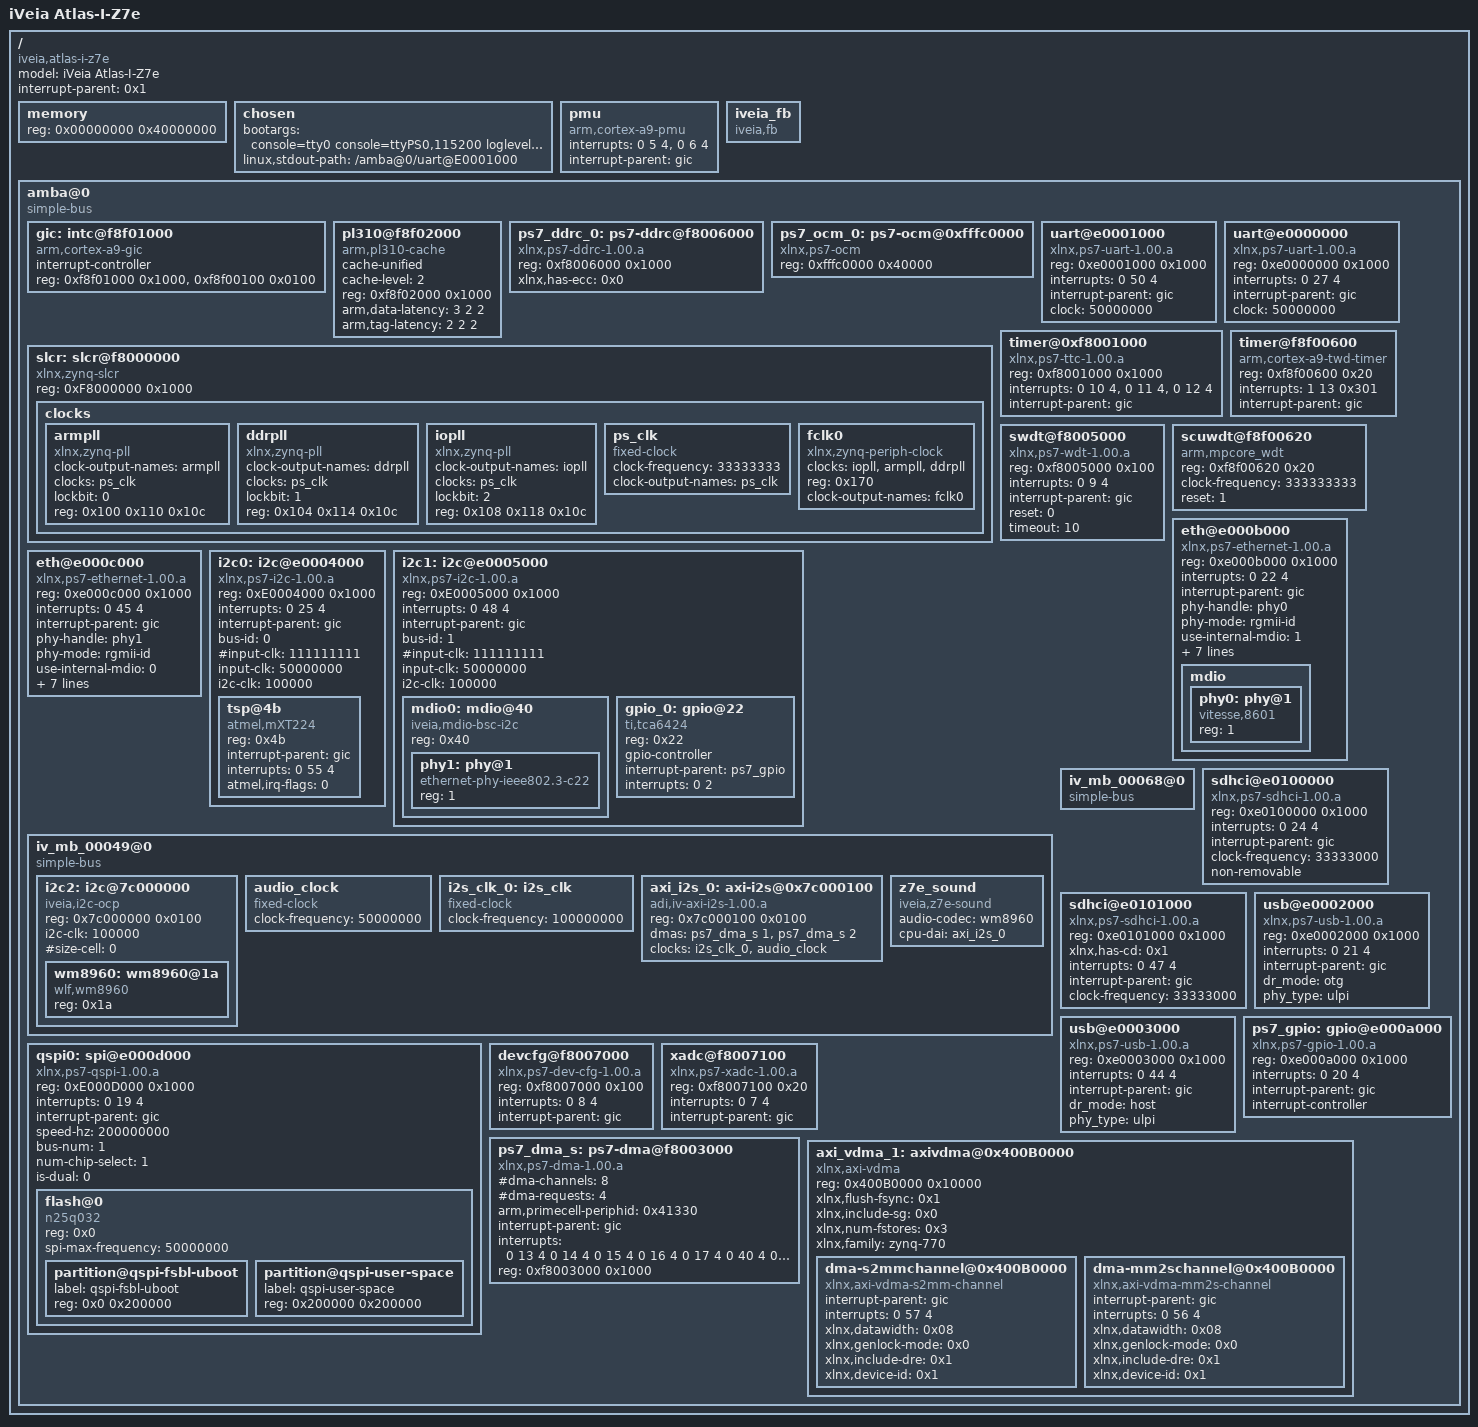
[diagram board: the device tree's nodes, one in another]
/dts-v1/;

/ {
	model = "iVeia Atlas-I-Z7e";
	compatible = "iveia,atlas-i-z7e";
	#address-cells = <0x1>;
	#size-cells = <0x1>;
	interrupt-parent = <0x1>;

	memory {
		device_type = "memory";
		reg = <0x00000000 0x40000000>;
	};
	chosen {
		bootargs = "console=tty0 console=ttyPS0,115200 loglevel=9 qemu=1 root=/dev/ram rw qemu=1 ip=192.168.1.10:::255.255.255.0:ZC702:eth0 earlyprintk mem=768M vram=256M";
//		bootargs = "console=ttyPS0,115200 root=/dev/mmcblk0p3 rw earlyprintk rootfstype=ext4 rootwait devtmpfs.mount=0";
		linux,stdout-path = "/amba@0/uart@E0001000";
	};

	pmu {
		compatible = "arm,cortex-a9-pmu";
		interrupts = <0 5 4>, <0 6 4>;
		interrupt-parent = <&gic>;
	};

	iveia_fb {
		compatible = "iveia,fb";
	};

	amba@0 {
		compatible = "simple-bus";
		#address-cells = <0x1>;
		#size-cells = <0x1>;
		ranges;

		gic: intc@f8f01000 {
			interrupt-controller;
			compatible = "arm,cortex-a9-gic";
			#interrupt-cells = <3>;
			reg = <0xf8f01000 0x1000>,
			      <0xf8f00100 0x0100>;
		};

		pl310@f8f02000 {
			compatible = "arm,pl310-cache";
			cache-unified;
			cache-level = <2>;
			reg = <0xf8f02000 0x1000>;
			arm,data-latency = <3 2 2>;
			arm,tag-latency = <2 2 2>;
		};

		ps7_ddrc_0: ps7-ddrc@f8006000 {
			compatible = "xlnx,ps7-ddrc-1.00.a", "xlnx,ps7-ddrc";
			reg = <0xf8006000 0x1000>;
			xlnx,has-ecc = <0x0>;
		} ;

		ps7_ocm_0: ps7-ocm@0xfffc0000 {
			compatible = "xlnx,ps7-ocm";
			reg = <0xfffc0000 0x40000>; /* 256k */
		};

		uart@e0001000 {
			compatible = "xlnx,ps7-uart-1.00.a";
			reg = <0xe0001000 0x1000>;
			interrupts = <0 50 4>;
			interrupt-parent = <&gic>;
			clock = <50000000>;
		};

		uart@e0000000 {
			compatible = "xlnx,ps7-uart-1.00.a";
			reg = <0xe0000000 0x1000>;
			interrupts = < 0 27 4 >;
			interrupt-parent = <&gic>;
			clock = <50000000>;
		};

		slcr: slcr@f8000000 {
			compatible = "xlnx,zynq-slcr";
			reg = <0xF8000000 0x1000>;
			clocks {
				#address-cells = <1>;
				#size-cells = <0>;	
				armpll: armpll {
                                        #clock-cells = <0>;
                                        clock-output-names = "armpll";
                                        clocks = <&ps_clk>;
                                        compatible = "xlnx,zynq-pll";
                                        lockbit = <0>;
                                        reg = < 0x100 0x110 0x10c >;
                                } ;
                                ddrpll: ddrpll {
                                        #clock-cells = <0>;
                                        clock-output-names = "ddrpll";
                                        clocks = <&ps_clk>;
                                        compatible = "xlnx,zynq-pll";
                                        lockbit = <1>;
                                        reg = < 0x104 0x114 0x10c >;
                                } ;
                                iopll: iopll {
                                        #clock-cells = <0>;
                                        clock-output-names = "iopll";
                                        clocks = <&ps_clk>;
                                        compatible = "xlnx,zynq-pll";
                                        lockbit = <2>;
                                        reg = < 0x108 0x118 0x10c >;
                                } ;
                                ps_clk: ps_clk {
                                        #clock-cells = <0>;
                                        clock-frequency = <33333333>;
                                        clock-output-names = "ps_clk";
                                        compatible = "fixed-clock";
                                } ;
				fclk0: fclk0 {
					#clock-cells = <1>;
					compatible = "xlnx,zynq-periph-clock";
					clocks = <&iopll &armpll &ddrpll>;
					reg = <0x170>;
					clock-output-names = "fclk0";
				} ;
			} ;
		};

		timer@0xf8001000 {
			compatible = "xlnx,ps7-ttc-1.00.a";
			reg = <0xf8001000 0x1000>;
			interrupts = <0 10 4>,<0 11 4>,<0 12 4>;
			interrupt-parent = <&gic>;
		};

		timer@f8f00600 {
			compatible = "arm,cortex-a9-twd-timer";
			reg = <0xf8f00600 0x20>;
			interrupts = <1 13 0x301>;
			interrupt-parent = <&gic>;
		};

		swdt@f8005000 {
			device_type = "watchdog";
			compatible = "xlnx,ps7-wdt-1.00.a";
			reg = <0xf8005000 0x100>;
			interrupts = <0 9 4>;
			interrupt-parent = <&gic>;
			reset = <0>;
			timeout = <10>;
		};

		scuwdt@f8f00620 {
			device_type = "watchdog";
			compatible = "arm,mpcore_wdt";
			reg = <0xf8f00620 0x20>;
			clock-frequency = <333333333>;
			reset = <1>;
		};

		eth@e000b000 {
			compatible = "xlnx,ps7-ethernet-1.00.a";
			reg = <0xe000b000 0x1000>;
			interrupts = <0 22 4>;
			interrupt-parent = <&gic>;
			phy-handle = <&phy0>;
			phy-mode = "rgmii-id";
			use-internal-mdio = <1>;
			xlnx,ptp-enet-clock = <111111111>;
			xlnx,slcr-div0-1000Mbps = <8>;
			xlnx,slcr-div0-100Mbps = <8>;
			xlnx,slcr-div0-10Mbps = <8>;
			xlnx,slcr-div1-1000Mbps = <1>;
			xlnx,slcr-div1-100Mbps = <5>;
			xlnx,slcr-div1-10Mbps = <50>;
			#address-cells = <0x1>;
			#size-cells = <0x0>;
			mdio {
				#address-cells = <1>;
				#size-cells = <0>;
				phy0: phy@1 {
					compatible = "vitesse,8601";
					device_type = "ethernet-phy";
					reg = <1>;
				} ;
			} ;

		};


		eth@e000c000 {
			compatible = "xlnx,ps7-ethernet-1.00.a";
			reg = <0xe000c000 0x1000>;
			interrupts = <0 45 4>;
			interrupt-parent = <&gic>;
			phy-handle = <&phy1>;
			phy-mode = "rgmii-id";
			use-internal-mdio = <0>;
			xlnx,ptp-enet-clock = <111111111>;
			xlnx,slcr-div0-1000Mbps = <8>;
			xlnx,slcr-div0-100Mbps = <8>;
			xlnx,slcr-div0-10Mbps = <8>;
			xlnx,slcr-div1-1000Mbps = <1>;
			xlnx,slcr-div1-100Mbps = <5>;
			xlnx,slcr-div1-10Mbps = <50>;
			#address-cells = <0x1>;
			#size-cells = <0x0>;
		};

		i2c0: i2c@e0004000 {
			compatible = "xlnx,ps7-i2c-1.00.a";
			reg = <0xE0004000 0x1000>;
			interrupts = <0 25 4>;
			interrupt-parent = <&gic>;
			bus-id = <0>;
			#input-clk = <111111111>;
			input-clk = <50000000>;
			i2c-clk = <100000>;

			#address-cells = <1>;
			#size-cells = <0>;
			tsp@4b {
				compatible = "atmel,mXT224";
				#address-cells = <1>;
				#size-cells = <0>;
				reg = <0x4b>;
			
				interrupt-parent = <&gic>;
				interrupts = <0 55 4>;
	
				atmel,irq-flags = <0>;
			};
		};

		i2c1: i2c@e0005000 {
			compatible = "xlnx,ps7-i2c-1.00.a";
			reg = <0xE0005000 0x1000>;
			interrupts = <0 48 4>;
			interrupt-parent = <&gic>;
			bus-id = <1>;
			#input-clk = <111111111>;
			input-clk = <50000000>;
			i2c-clk = <100000>;

                        #address-cells = <1>;
                        #size-cells = <0>;

			mdio0: mdio@40 {
                compatible = "iveia,mdio-bsc-i2c";
                reg = <0x40>;
				#address-cells = <1>;
				#size-cells = <0>;

				phy1: phy@1 {
					compatible = "ethernet-phy-ieee802.3-c22";
					device_type = "ethernet-phy";
					reg = <1>;
				} ;

			} ;

		    gpio_0: gpio@22 {
			    compatible = "ti,tca6424";
			    reg = <0x22>;
			    gpio-controller;
			    #gpio-cells = <2>;

                interrupt-parent = <&ps7_gpio>;
                interrupts = <0 2>;

		    };

		};
	iv_mb_00049@0 { //Atlas-I-Z7e
		compatible = "simple-bus";
		#address-cells = <0x1>;
		#size-cells = <0x1>;
		ranges;

		i2c2: i2c@7c000000 {
			compatible = "iveia,i2c-ocp";
			reg = <0x7c000000 0x0100>;
			i2c-clk = <100000>;

			

			#address-cells = <1>;
			#size-cell = <0>;
			wm8960: wm8960@1a {
				compatible = "wlf,wm8960";
				#address-cells = <1>;
				#size-cells = <0>;
				reg = <0x1a>;
			};
		};

                audio_clock: audio_clock {
                        compatible = "fixed-clock";
                        #clock-cells = <0>;
                        clock-frequency = <50000000>;
                };

                i2s_clk_0: i2s_clk {
                        compatible = "fixed-clock";
                        #clock-cells = <0>;
                        clock-frequency = <100000000>;
                };

                axi_i2s_0: axi-i2s@0x7c000100 {
                        compatible = "adi,iv-axi-i2s-1.00.a";
                        reg = <0x7c000100 0x0100>;
                        dmas = <&ps7_dma_s 1 &ps7_dma_s 2>;
                        dma-names = "tx", "rx";
                        clocks = <&i2s_clk_0 &audio_clock>;
                        clock-names = "axi", "i2s";
                };

                z7e_sound {
                        compatible = "iveia,z7e-sound";
                        audio-codec = <&wm8960>;
                        cpu-dai = <&axi_i2s_0>;
                };
    };


	iv_mb_00068@0 { //Atlas-ii_z7x
		compatible = "simple-bus";
		#address-cells = <0x1>;
		#size-cells = <0x1>;
		ranges;

    };

		sdhci@e0100000 {
                        compatible = "xlnx,ps7-sdhci-1.00.a";
                        reg = <0xe0100000 0x1000>;
                        interrupts = <0 24 4>;
                        interrupt-parent = <&gic>;
                        clock-frequency = <33333000>;
                        non-removable;
                };

		sdhci@e0101000 {
			compatible = "xlnx,ps7-sdhci-1.00.a";
			reg = <0xe0101000 0x1000>;
			xlnx,has-cd = <0x1>;
			interrupts = <0 47 4>;
			interrupt-parent = <&gic>;
			clock-frequency = <33333000>;
		};

		usb@e0002000 {
			compatible = "xlnx,ps7-usb-1.00.a";
			reg = <0xe0002000 0x1000>;
			interrupts = <0 21 4>;
			interrupt-parent = <&gic>;
			dr_mode = "otg";
			phy_type = "ulpi";
		};

		usb@e0003000 {
			compatible = "xlnx,ps7-usb-1.00.a";
			reg = <0xe0003000 0x1000>;
			interrupts = <0 44 4>;
			interrupt-parent = <&gic>;
			dr_mode = "host";
			phy_type = "ulpi";
		};

		ps7_gpio: gpio@e000a000 {
			compatible = "xlnx,ps7-gpio-1.00.a";
			reg = <0xe000a000 0x1000>;
			interrupts = <0 20 4>;
			interrupt-parent = <&gic>;

            interrupt-controller;
            #interrupt-cells = <2>;

		};


		qspi0: spi@e000d000 {
			compatible = "xlnx,ps7-qspi-1.00.a";
			reg = <0xE000D000 0x1000>;
			interrupts = <0 19 4>;
			interrupt-parent = <&gic>;
			speed-hz = <200000000>;
			bus-num = <1>;
			num-chip-select = <1>;
			#address-cells = <1>;
			#size-cells = <0>;
			is-dual = <0>;
			flash@0 {
				compatible = "n25q032";
				reg = <0x0>;
				spi-max-frequency = <50000000>;
				#address-cells = <1>;
				#size-cells = <1>;
				partition@qspi-fsbl-uboot {
					label = "qspi-fsbl-uboot";
					reg = <0x0 0x200000>;
				};
				partition@qspi-user-space{
					label = "qspi-user-space";
					reg = <0x200000 0x200000>;
				};
			};
		};

		devcfg@f8007000 {
			compatible = "xlnx,ps7-dev-cfg-1.00.a";
			reg = <0xf8007000 0x100>;
			interrupts = <0 8 4>;
			interrupt-parent = <&gic>;
		};

		xadc@f8007100 {
			compatible = "xlnx,ps7-xadc-1.00.a";
			reg = <0xf8007100 0x20>;
			interrupts = <0 7 4>;
			interrupt-parent = <&gic>;
		};

		ps7_dma_s: ps7-dma@f8003000 {
			#dma-cells = <1>;
			#dma-channels = <8>;
			#dma-requests = <4>;
			arm,primecell-periphid = <0x41330>;
			compatible = "xlnx,ps7-dma-1.00.a", "arm,primecell", "arm,pl330";
			interrupt-parent = <&gic>;
			interrupts = <0 13 4 0 14 4 0 15 4 0 16 4 0 17 4 0 40 4 0 41 4 0 42 4 0 43 4>;
			reg = <0xf8003000 0x1000>;
		};

		axi_vdma_1: axivdma@0x400B0000 {
			#address-cells = <1>;
			#size-cells = <1>;
			compatible = "xlnx,axi-vdma";
			ranges = <0x400B0000 0x400B0000 0x10000>;
			reg = <0x400B0000 0x10000>;
			xlnx,flush-fsync = <0x1>;
			xlnx,include-sg = <0x0>;
			xlnx,num-fstores = <0x3>;
			xlnx,family = "zynq-770";
			dma-s2mmchannel@0x400B0000 {
				compatible = "xlnx,axi-vdma-s2mm-channel";
				interrupt-parent = <&gic>;
				interrupts = <0 57 4>;
				xlnx,datawidth = <0x08>;
				xlnx,genlock-mode = <0x0>;
				xlnx,include-dre = <0x1>;
				xlnx,device-id = <0x1>;
			};
			dma-mm2schannel@0x400B0000 {
				compatible = "xlnx,axi-vdma-mm2s-channel";
				interrupt-parent = <&gic>;
				interrupts = <0 56 4>;
				xlnx,datawidth = <0x08>;
				xlnx,genlock-mode = <0x0>;
				xlnx,include-dre = <0x1>;
				xlnx,device-id = <0x1>;
			};
		};

	};
};
